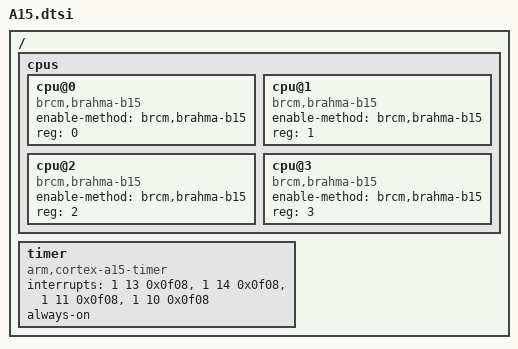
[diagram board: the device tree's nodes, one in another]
/ {
	cpus {
		#address-cells = <1>;
		#size-cells = <0>;

		cpu@0 {
			device_type = "cpu";
			enable-method = "brcm,brahma-b15";
			compatible = "brcm,brahma-b15", "arm,cortex-a15";
			reg = <0>;
		};

		cpu@1 {
			device_type = "cpu";
			enable-method = "brcm,brahma-b15";
			compatible = "brcm,brahma-b15", "arm,cortex-a15";
			reg = <1>;
		};

		cpu@2 {
			device_type = "cpu";
			enable-method = "brcm,brahma-b15";
			compatible = "brcm,brahma-b15", "arm,cortex-a15";
			reg = <2>;
		};

		cpu@3 {
			device_type = "cpu";
			enable-method = "brcm,brahma-b15";
			compatible = "brcm,brahma-b15", "arm,cortex-a15";
			reg = <3>;
		};
	};

	timer {
		compatible = "arm,cortex-a15-timer",
			     "arm,armv7-timer";
		interrupts = <1 13 0x0f08>,
			     <1 14 0x0f08>,
			     <1 11 0x0f08>,
			     <1 10 0x0f08>;
		always-on;
	};

};
